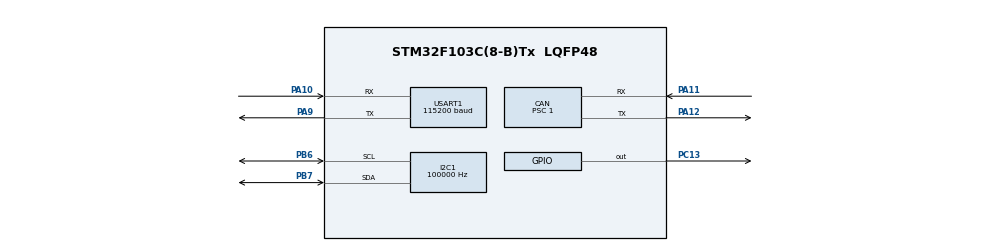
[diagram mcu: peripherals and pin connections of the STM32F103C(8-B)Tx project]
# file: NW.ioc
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CAN.BS1=CAN_BS1_13TQ
CAN.BS2=CAN_BS2_2TQ
CAN.CalculateBaudRate=500000
CAN.CalculateTimeBit=2000
CAN.CalculateTimeQuantum=125.0
CAN.NART=DISABLE
CAN.Prescaler=1
I2C1.AddressingMode=I2C_ADDRESSINGMODE_7BIT
I2C1.ClockSpeed=100000
I2C1.DualAddressMode=I2C_DUALADDRESS_DISABLE
I2C1.GeneralCallMode=I2C_GENERALCALL_DISABLE
I2C1.NoStretchMode=I2C_NOSTRETCH_DISABLE
I2C1.OwnAddress1=0
Mcu.Family=STM32F1
Mcu.Name=STM32F103C(8-B)Tx
Mcu.Package=LQFP48
NVIC.PriorityGroup=NVIC_PRIORITYGROUP_4
PA10.Mode=Asynchronous
PA10.Signal=USART1_RX
PA11.Mode=CAN_Activate
PA11.Signal=CAN_RX
PA12.Mode=CAN_Activate
PA12.Signal=CAN_TX
PA13.Mode=Serial_Wire
PA13.Signal=SYS_JTMS-SWDIO
PA14.Mode=Serial_Wire
PA14.Signal=SYS_JTCK-SWCLK
PA9.Mode=Asynchronous
PA9.Signal=USART1_TX
PB6.Mode=I2C
PB6.Signal=I2C1_SCL
PB7.Mode=I2C
PB7.Signal=I2C1_SDA
PC13-TAMPER-RTC.Signal=GPIO_Output
ProjectManager.HeapSize=0x200
ProjectManager.StackSize=0x400
ProjectManager.TargetToolchain=CMake
RCC.APB1Freq_Value=8000000
RCC.APB2Freq_Value=8000000
USART1.BaudRate=115200
USART1.Parity=PARITY_NONE
USART1.StopBits=STOPBITS_1
USART1.VirtualMode=VM_ASYNC
USART1.VirtualMode-Asynchronous=VM_ASYNC
USART1.WordLength=WORDLENGTH_8B
board=custom

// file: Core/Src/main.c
/* USER CODE BEGIN Header */
/**
  ******************************************************************************
  * @file           : main.c
  * @brief          : Main program body
  ******************************************************************************
  * @attention
  *
  * Copyright (c) 2026 STMicroelectronics.
  * All rights reserved.
  *
  * This software is licensed under terms that can be found in the LICENSE file
  * in the root directory of this software component.
  * If no LICENSE file comes with this software, it is provided AS-IS.
  *
  ******************************************************************************
  */
/* USER CODE END Header */
#include "main.h"

/* USER CODE BEGIN PD */
#define LED_Pin        GPIO_PIN_13
#define LED_GPIO_Port  GPIOC

/* USER CODE END PD */

CAN_HandleTypeDef hcan;

I2C_HandleTypeDef hi2c1;

UART_HandleTypeDef huart1;

void SystemClock_Config(void);
static void MX_GPIO_Init(void);
static void MX_I2C1_Init(void);
static void MX_USART1_UART_Init(void);
static void MX_CAN_Init(void);

int main(void)
{

  /* MCU Configuration--------------------------------------------------------*/

  /* Reset of all peripherals, Initializes the Flash interface and the Systick. */
  HAL_Init();

  /* Configure the system clock */
  SystemClock_Config();

  /* Initialize all configured peripherals */
  MX_GPIO_Init();
  MX_I2C1_Init();
  MX_USART1_UART_Init();
  MX_CAN_Init();

  /* Infinite loop */
  /* USER CODE BEGIN WHILE */
  while (1)
  {
    HAL_GPIO_TogglePin(GPIOC,GPIO_PIN_13);
    HAL_Delay(500);
    /* USER CODE END WHILE */

    /* USER CODE BEGIN 3 */
    HAL_GPIO_TogglePin(LED_GPIO_Port, LED_Pin);
    HAL_Delay(500);
  }
  /* USER CODE END 3 */
}

void SystemClock_Config(void)
{
  RCC_OscInitTypeDef RCC_OscInitStruct = {0};
  RCC_ClkInitTypeDef RCC_ClkInitStruct = {0};

  /** Initializes the RCC Oscillators according to the specified parameters
  * in the RCC_OscInitTypeDef structure.
  */
  RCC_OscInitStruct.OscillatorType = RCC_OSCILLATORTYPE_HSI;
  RCC_OscInitStruct.HSIState = RCC_HSI_ON;
  RCC_OscInitStruct.HSICalibrationValue = RCC_HSICALIBRATION_DEFAULT;
  RCC_OscInitStruct.PLL.PLLState = RCC_PLL_NONE;
  if (HAL_RCC_OscConfig(&RCC_OscInitStruct) != HAL_OK)
  {
    Error_Handler();
  }

  /** Initializes the CPU, AHB and APB buses clocks
  */
  RCC_ClkInitStruct.ClockType = RCC_CLOCKTYPE_HCLK|RCC_CLOCKTYPE_SYSCLK
                              |RCC_CLOCKTYPE_PCLK1|RCC_CLOCKTYPE_PCLK2;
  RCC_ClkInitStruct.SYSCLKSource = RCC_SYSCLKSOURCE_HSI;
  RCC_ClkInitStruct.AHBCLKDivider = RCC_SYSCLK_DIV1;
  RCC_ClkInitStruct.APB1CLKDivider = RCC_HCLK_DIV1;
  RCC_ClkInitStruct.APB2CLKDivider = RCC_HCLK_DIV1;

  if (HAL_RCC_ClockConfig(&RCC_ClkInitStruct, FLASH_LATENCY_0) != HAL_OK)
  {
    Error_Handler();
  }
}

static void MX_CAN_Init(void)
{

  hcan.Instance = CAN1;
  hcan.Init.Prescaler = 1;
  hcan.Init.Mode = CAN_MODE_NORMAL;
  hcan.Init.SyncJumpWidth = CAN_SJW_1TQ;
  hcan.Init.TimeSeg1 = CAN_BS1_13TQ;
  hcan.Init.TimeSeg2 = CAN_BS2_2TQ;
  hcan.Init.TimeTriggeredMode = DISABLE;
  hcan.Init.AutoBusOff = DISABLE;
  hcan.Init.AutoWakeUp = DISABLE;
  hcan.Init.AutoRetransmission = DISABLE;
  hcan.Init.ReceiveFifoLocked = DISABLE;
  hcan.Init.TransmitFifoPriority = DISABLE;
  if (HAL_CAN_Init(&hcan) != HAL_OK)
  {
    Error_Handler();
  }

}

static void MX_I2C1_Init(void)
{

  hi2c1.Instance = I2C1;
  hi2c1.Init.ClockSpeed = 100000;
  hi2c1.Init.DutyCycle = I2C_DUTYCYCLE_2;
  hi2c1.Init.OwnAddress1 = 0;
  hi2c1.Init.AddressingMode = I2C_ADDRESSINGMODE_7BIT;
  hi2c1.Init.DualAddressMode = I2C_DUALADDRESS_DISABLE;
  hi2c1.Init.OwnAddress2 = 0;
  hi2c1.Init.GeneralCallMode = I2C_GENERALCALL_DISABLE;
  hi2c1.Init.NoStretchMode = I2C_NOSTRETCH_DISABLE;
  if (HAL_I2C_Init(&hi2c1) != HAL_OK)
  {
    Error_Handler();
  }

}

static void MX_USART1_UART_Init(void)
{

  huart1.Instance = USART1;
  huart1.Init.BaudRate = 115200;
  huart1.Init.WordLength = UART_WORDLENGTH_8B;
  huart1.Init.StopBits = UART_STOPBITS_1;
  huart1.Init.Parity = UART_PARITY_NONE;
  huart1.Init.Mode = UART_MODE_TX_RX;
  huart1.Init.HwFlowCtl = UART_HWCONTROL_NONE;
  huart1.Init.OverSampling = UART_OVERSAMPLING_16;
  if (HAL_UART_Init(&huart1) != HAL_OK)
  {
    Error_Handler();
  }

}

static void MX_GPIO_Init(void)
{
  GPIO_InitTypeDef GPIO_InitStruct = {0};

  /* GPIO Ports Clock Enable */
  __HAL_RCC_GPIOC_CLK_ENABLE();
  __HAL_RCC_GPIOA_CLK_ENABLE();
  __HAL_RCC_GPIOB_CLK_ENABLE();

  /*Configure GPIO pin Output Level */
  HAL_GPIO_WritePin(GPIOC, GPIO_PIN_13, GPIO_PIN_RESET);

  /*Configure GPIO pin : PC13 */
  GPIO_InitStruct.Pin = GPIO_PIN_13;
  GPIO_InitStruct.Mode = GPIO_MODE_OUTPUT_PP;
  GPIO_InitStruct.Pull = GPIO_NOPULL;
  GPIO_InitStruct.Speed = GPIO_SPEED_FREQ_LOW;
  HAL_GPIO_Init(GPIOC, &GPIO_InitStruct);

}

void Error_Handler(void)
{
  __disable_irq();
  while (1)
  {
  }
}
